AUTOSAR XML (schema 00051)
package /Components
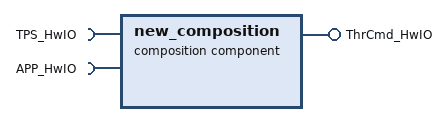
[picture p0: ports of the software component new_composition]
  composition sw component type new_composition
    require port TPS_HwIO: required-interface=TPS_HwIO
    require port APP_HwIO: required-interface=APP_HwIO
    provide port ThrCmd_HwIO: provided-interface=ThrCmd_HwIO
    4 x component:
      Throttle_sensor: type=ThrottlePositionSensor
      Pedal_sensor: type=AccelerationPedalPositionSensor
      Controller: type=Controller
      Actuator: type=ThrottlePositionActuator
    connect Controller.ThrCmd_Percent -> Actuator.ThrCmd_Percent
    connect Pedal_sensor.APP_Percent -> Controller.APP_Percent
    connect Throttle_sensor.TPS_Percent -> Controller.TPS_Percent
    delegate Actuator.ThrCmd_HwIO <-> outer port ThrCmd_HwIO
    delegate Throttle_sensor.TPS_HwIO <-> outer port TPS_HwIO
    delegate Pedal_sensor.APP_HwIO <-> outer port APP_HwIO
